AUTOSAR XML (schema 4-2-2)
package /EB/SoftwareComponents
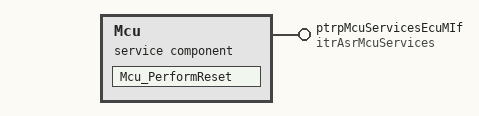
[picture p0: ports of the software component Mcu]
  service sw component type Mcu: category=ASR_Interfaces
    provide port ptrpMcuServicesEcuMIf: provided-interface=itrAsrMcuServices
    behavior Mcu_IB: handle-termination-and-restart=NO-SUPPORT
      runnable Mcu_PerformReset
package /EB/TriggerInterfaces
  trigger interface itrAsrMcuServices
    trigger Mcu_Init: trigger-period={cse-code=1000, cse-code-factor=0}
    trigger Mcu_PerformReset: trigger-period={cse-code=1000, cse-code-factor=0}
